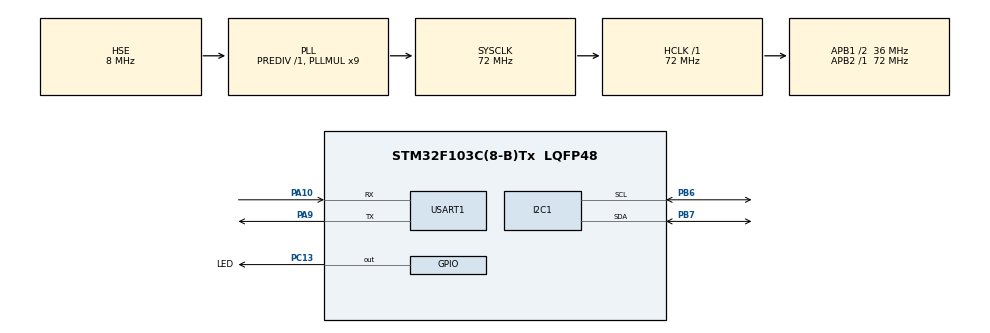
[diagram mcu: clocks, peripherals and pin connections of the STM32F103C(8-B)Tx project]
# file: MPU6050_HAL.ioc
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I2C1.I2C_Mode=I2C_Fast
Mcu.Family=STM32F1
Mcu.Name=STM32F103C(8-B)Tx
Mcu.Package=LQFP48
NVIC.PriorityGroup=NVIC_PRIORITYGROUP_4
PA10.Mode=Asynchronous
PA10.Signal=USART1_RX
PA13.Mode=Serial_Wire
PA13.Signal=SYS_JTMS-SWDIO
PA14.Mode=Serial_Wire
PA14.Signal=SYS_JTCK-SWCLK
PA9.Mode=Asynchronous
PA9.Signal=USART1_TX
PB6.Mode=I2C
PB6.Signal=I2C1_SCL
PB7.Mode=I2C
PB7.Signal=I2C1_SDA
PC13-TAMPER-RTC.GPIO_Label=LED
PC13-TAMPER-RTC.GPIO_Speed=GPIO_SPEED_FREQ_MEDIUM
PC13-TAMPER-RTC.PinState=GPIO_PIN_RESET
PC13-TAMPER-RTC.Signal=GPIO_Output
PD0-OSC_IN.Mode=HSE-External-Oscillator
PD0-OSC_IN.Signal=RCC_OSC_IN
PD1-OSC_OUT.Mode=HSE-External-Oscillator
PD1-OSC_OUT.Signal=RCC_OSC_OUT
ProjectManager.HeapSize=0x200
ProjectManager.StackSize=0x400
ProjectManager.TargetToolchain=MDK-ARM V5.27
RCC.AHBFreq_Value=72000000
RCC.APB1CLKDivider=RCC_HCLK_DIV2
RCC.APB1Freq_Value=36000000
RCC.APB1TimFreq_Value=72000000
RCC.APB2Freq_Value=72000000
RCC.APB2TimFreq_Value=72000000
RCC.HCLKFreq_Value=72000000
RCC.PLLMUL=RCC_PLL_MUL9
RCC.PLLSourceVirtual=RCC_PLLSOURCE_HSE
RCC.SYSCLKFreq_VALUE=72000000
RCC.SYSCLKSource=RCC_SYSCLKSOURCE_PLLCLK
RCC.USBFreq_Value=72000000
USART1.VirtualMode=VM_ASYNC
board=custom

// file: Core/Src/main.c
/* USER CODE BEGIN Header */
/**
  ******************************************************************************
  * @file           : main.c
  * @brief          : Main program body
  ******************************************************************************
  * @attention
  *
  * <h2><center>&copy; Copyright (c) 2021 STMicroelectronics.
  * All rights reserved.</center></h2>
  *
  * This software component is licensed by ST under BSD 3-Clause license,
  * the "License"; You may not use this file except in compliance with the
  * License. You may obtain a copy of the License at:
  *                        opensource.org/licenses/BSD-3-Clause
  *
  ******************************************************************************
  */
/*MPU6050引脚连接说明:
		STM32C8T6										MPU6050
			3.3V													VCC
			GND													GND
			PB6													SCL
			PB7													SDA
*/
/*串口连接说明:
		STM32C8T6										TTL转USB
			3.3V													3.3V
			GND													GND
			PA9													RXD
*/
/* USER CODE END Header */
#include "main.h"
#include "i2c.h"
#include "usart.h"
#include "gpio.h"

/* USER CODE BEGIN Includes */
/*头文件引入*/
#include <stdio.h>
#include "mpu6050.h"
#include "inv_mpu.h"
/* USER CODE END Includes */

void SystemClock_Config(void);

/* USER CODE BEGIN 0 */
int fputc(int ch, FILE *f)
{ //printf重定向
  HAL_UART_Transmit(&huart1, (uint8_t *)&ch, 1, 0xFFFF);
  return (ch);
}
/* USER CODE END 0 */

int main(void)
{

  /* MCU Configuration--------------------------------------------------------*/

  /* Reset of all peripherals, Initializes the Flash interface and the Systick. */
  HAL_Init();

  /* Configure the system clock */
  SystemClock_Config();

  /* Initialize all configured peripherals */
  MX_GPIO_Init();
  MX_I2C1_Init();
  MX_USART1_UART_Init();
  /* USER CODE BEGIN 2 */
  HAL_GPIO_WritePin(LED_GPIO_Port, LED_Pin, GPIO_PIN_SET); //关闭核心板的led

  float pitch, roll, yaw;                                  //欧拉角
  printf("-- Mpu6050 Project Start -- \r\n");

  /*******iic读取器件ID*****/
  uint8_t recv = 0x00;
  HAL_I2C_Mem_Read(&hi2c1, (0x68 << 1), 0x75, I2C_MEMADD_SIZE_8BIT, &recv, 1, 0xfff);
  if (recv == 0x68)
  {
    printf("mpu6050 ID Read: OK at 0x68\r\n");
  }
  else
  {
    printf("Err mpu id:0x%x\r\n", recv);
  }

  /*******DMP初始化*******/
  while (mpu_dmp_init())
  {
    HAL_Delay(200);
  }

  /* USER CODE EN  D 2 */

  /* Infinite loop */
  /* USER CODE BEGIN WHILE */
  while (1)
  {
    HAL_Delay(2);
    if (mpu_dmp_get_data(&pitch, &roll, &yaw) == 0) //DMP读取欧拉角
    {
      HAL_GPIO_TogglePin(LED_GPIO_Port, LED_Pin); //led电平翻转
      printf("%f,%f,%f\r\n", pitch, roll, yaw);   //串口打印欧拉角
    }
    /* USER CODE END WHILE */

  }
}

void SystemClock_Config(void)
{
  RCC_OscInitTypeDef RCC_OscInitStruct = {0};
  RCC_ClkInitTypeDef RCC_ClkInitStruct = {0};

  /** Initializes the RCC Oscillators according to the specified parameters
  * in the RCC_OscInitTypeDef structure.
  */
  RCC_OscInitStruct.OscillatorType = RCC_OSCILLATORTYPE_HSE;
  RCC_OscInitStruct.HSEState = RCC_HSE_ON;
  RCC_OscInitStruct.HSEPredivValue = RCC_HSE_PREDIV_DIV1;
  RCC_OscInitStruct.HSIState = RCC_HSI_ON;
  RCC_OscInitStruct.PLL.PLLState = RCC_PLL_ON;
  RCC_OscInitStruct.PLL.PLLSource = RCC_PLLSOURCE_HSE;
  RCC_OscInitStruct.PLL.PLLMUL = RCC_PLL_MUL9;
  if (HAL_RCC_OscConfig(&RCC_OscInitStruct) != HAL_OK)
  {
    Error_Handler();
  }
  /** Initializes the CPU, AHB and APB buses clocks
  */
  RCC_ClkInitStruct.ClockType = RCC_CLOCKTYPE_HCLK|RCC_CLOCKTYPE_SYSCLK
                              |RCC_CLOCKTYPE_PCLK1|RCC_CLOCKTYPE_PCLK2;
  RCC_ClkInitStruct.SYSCLKSource = RCC_SYSCLKSOURCE_PLLCLK;
  RCC_ClkInitStruct.AHBCLKDivider = RCC_SYSCLK_DIV1;
  RCC_ClkInitStruct.APB1CLKDivider = RCC_HCLK_DIV2;
  RCC_ClkInitStruct.APB2CLKDivider = RCC_HCLK_DIV1;

  if (HAL_RCC_ClockConfig(&RCC_ClkInitStruct, FLASH_LATENCY_2) != HAL_OK)
  {
    Error_Handler();
  }
}

void Error_Handler(void)
{
  __disable_irq();
  while (1)
  {
  }
}

/************************ (C) COPYRIGHT STMicroelectronics *****END OF FILE****/
